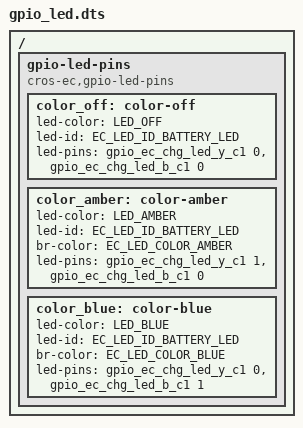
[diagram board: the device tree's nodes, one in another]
/* Copyright 2022 The Chromium OS Authors. All rights reserved.
 * Use of this source code is governed by a BSD-style license that can be
 * found in the LICENSE file.
 */

/ {
	gpio-led-pins {
		compatible = "cros-ec,gpio-led-pins";

		color_off: color-off {
			led-color = "LED_OFF";
			led-id = "EC_LED_ID_BATTERY_LED";
			led-pins = <&gpio_ec_chg_led_y_c1 0>,
				   <&gpio_ec_chg_led_b_c1 0>;
		};

		color_amber: color-amber {
			led-color = "LED_AMBER";
			led-id = "EC_LED_ID_BATTERY_LED";
			br-color = "EC_LED_COLOR_AMBER";
			led-pins = <&gpio_ec_chg_led_y_c1 1>,
				   <&gpio_ec_chg_led_b_c1 0>;
		};

		color_blue: color-blue {
			led-color = "LED_BLUE";
			led-id = "EC_LED_ID_BATTERY_LED";
			br-color = "EC_LED_COLOR_BLUE";
			led-pins = <&gpio_ec_chg_led_y_c1 0>,
				   <&gpio_ec_chg_led_b_c1 1>;
		};
	};
};
